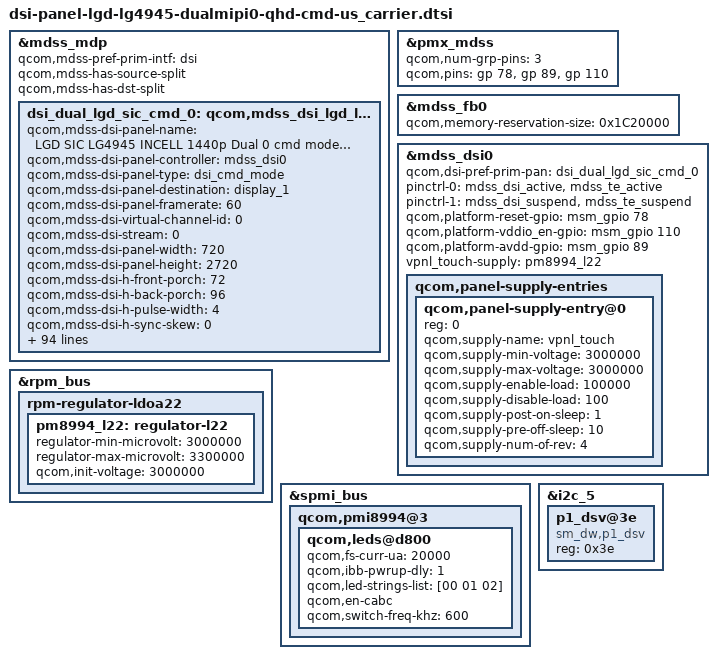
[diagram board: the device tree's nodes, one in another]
/* Copyright (c) 2014, Code Aurora Forum. All rights reserved.
 *
 * This program is free software; you can redistribute it and/or modify
 * it under the terms of the GNU General Public License version 2 and
 * only version 2 as published by the Free Software Foundation.
 *
 * This program is distributed in the hope that it will be useful,
 * but WITHOUT ANY WARRANTY; without even the implied warranty of
 * MERCHANTABILITY or FITNESS FOR A PARTICULAR PURPOSE.  See the
 * GNU General Public License for more details.
 */

&mdss_mdp {
	qcom,mdss-pref-prim-intf = "dsi";
	qcom,mdss-has-source-split;
	qcom,mdss-has-dst-split;
	/*/delete-property/ qcom,mdss-ad-off;*/

	dsi_dual_lgd_sic_cmd_0: qcom,mdss_dsi_lgd_lg4945_1440p_mipi0_cmd {
		qcom,mdss-dsi-panel-name = "LGD SIC LG4945 INCELL 1440p Dual 0 cmd mode dsi panel";
		qcom,mdss-dsi-panel-controller = <&mdss_dsi0>;
		qcom,mdss-dsi-panel-type = "dsi_cmd_mode";
		qcom,mdss-dsi-panel-destination = "display_1";
		qcom,mdss-dsi-panel-framerate = <60>;
		qcom,mdss-dsi-virtual-channel-id = <0>;
		qcom,mdss-dsi-stream = <0>;
		qcom,mdss-dsi-panel-width = <720>;
		qcom,mdss-dsi-panel-height = <2720>;
		qcom,mdss-dsi-h-front-porch = <72>;
		qcom,mdss-dsi-h-back-porch = <96>;
		qcom,mdss-dsi-h-pulse-width = <4>;
		qcom,mdss-dsi-h-sync-skew = <0>;
		qcom,mdss-dsi-v-back-porch = <43>;
		qcom,mdss-dsi-v-front-porch = <8>;
		qcom,mdss-dsi-v-pulse-width = <1>;
		qcom,mdss-dsi-h-left-border = <0>;
		qcom,mdss-dsi-h-right-border = <0>;
		qcom,mdss-dsi-v-top-border = <0>;
		qcom,mdss-dsi-v-bottom-border = <0>;
		qcom,mdss-dsi-bpp = <24>;
		qcom,mdss-dsi-color-order = "rgb_swap_rgb";
		qcom,mdss-dsi-underflow-color = <0xff>;
		qcom,mdss-dsi-border-color = <0>;
		qcom,mdss-dsi-h-sync-pulse = <0>;
		qcom,mdss-dsi-traffic-mode = "burst_mode";
		qcom,mdss-dsi-lane-map = "lane_map_0123";
		qcom,mdss-dsi-lane-hs = <1>;
		qcom,mdss-dsi-bllp-eof-power-mode;
		qcom,mdss-dsi-bllp-power-mode;
		qcom,cmd-sync-wait-broadcast;

		qcom,mdss-dsi-lane-0-state;
		qcom,mdss-dsi-lane-1-state;
		qcom,mdss-dsi-lane-2-state;
		qcom,mdss-dsi-lane-3-state;
		qcom,mdss-dsi-hor-line-idle = <0 40 256>,
						<40 120 128>,
						<120 240 64>;
		qcom,mdss-dsi-panel-timings = [D4 38 38 00 68 5E
									3A 3A 2C 03 04 00];
		qcom,mdss-dsi-reset-sequence = <1 10>, <0 10>, <1 10>;
		qcom,mdss-dsi-t-clk-post = <0x02>;
		lge,mdss-dsi-t-clk-post_for_jdi_ab = <0x32>;
		qcom,mdss-dsi-t-clk-pre = <0x2D>;
		qcom,mdss-dsi-bl-max-level = <4095>;
		qcom,mdss-dsi-dma-trigger = "trigger_sw";
		qcom,mdss-dsi-mdp-trigger = "none";
		qcom,mdss-dsi-bl-pmic-control-type = "bl_ctrl_wled";
		qcom,mdss-dsi-te-pin-select = <1>;
		qcom,mdss-dsi-wr-mem-start = <0x2c>;
		qcom,mdss-dsi-wr-mem-continue = <0x3c>;
		qcom,mdss-dsi-te-dcs-command = <1>;
		qcom,mdss-dsi-te-check-enable;
		qcom,mdss-dsi-te-using-te-pin;
		qcom,suspend-ulps-enabled;
		qcom,mdss-dsi-tx-eot-append;
		qcom,mdss-mdp-transfer-time-us = <15000>;
		/* Partial update */
		qcom,partial-update-enabled;
		qcom,partial-update-roi-merge;
		qcom,panel-roi-alignment = <8 8 4 4 32 32>;
		qcom,mdss-dsi-on-command = [ /*initset v0.9*/
			/* Page Address Set */
			39 01 00 00 00 00 05 2B 00 00 0A 9F
			/* Manufacturer Command Protection */
			15 01 00 00 00 00 02 B0 AC
			/* Touch timing setting to prevent tearing */
			39 01 00 00 00 00 03 44 0A 8C
			/* Tearing Effect Line on */
			15 01 00 00 00 00 02 35 00
			/* Write Control Display */
			15 01 00 00 00 00 02 53 24
			/* Write Display Brightness */
			15 01 00 00 00 00 02 51 FF
			/* Write Content Adaptive Brightness Control */
			15 01 00 00 00 00 02 55 81
			/* Display Control 1 */
			39 01 00 00 00 00 08 B3 0A 14 28 C8 1A 94 02
			/* Display Control 2 */
			39 01 00 00 00 00 0B B4 91 08 0A 0A 0A 0A 14 14 14 14
			/* Display Control 3 */
			39 01 00 00 00 00 0F B5 28 10 20 C8 22 09 09 01 01 00 68 E8 05 05
			/* Display Control 4 */
			39 01 00 00 00 00 06 B6 16 0F 00 08 0A
			/* Panel Setting */
			39 01 00 00 00 00 06 B8 60 91 A7 90 01
			/* Internal Oscillator Setting */
			39 01 00 00 00 00 03 C0 91 00
			/* Power Control 1 */
			39 01 00 00 00 00 06 C1 01 00 F0 C2 CF
			/* Power Control 2 */
			15 01 00 00 00 00 02 C2 CC
			/* Power Control 3 */
			39 01 00 00 00 00 06 C3 35 88 22 26 21
			/* Power Control 5 */
			39 01 00 00 00 00 08 C5 24 20 A0 25 14 34 02
			/* Abrupt Power Off Control */
			15 01 00 00 00 00 02 C9 9F
			/* U2 Control */
			39 01 00 00 00 00 0C CB 86 46 0F 77 06 01 16 0F 08 0A 36
			/* Touch Control */
			39 01 00 00 00 00 10 CD F0 4C 0D 3F 4F 22 22 01 0A 01 02 57 A8 64 64
			/* Positive Gamma Curve for Red */
			39 01 00 00 00 00 0E D0 00 12 1C 2B 36 3E 53 4B 41 36 2A 24 03
			/* Negative Gamma Curve for Red */
			39 01 00 00 00 00 0E D1 00 12 1C 2B 36 3E 53 4B 41 36 2A 24 03
			/* Positive Gamma Curve for  Green */
			39 01 00 00 00 00 0E D2 00 12 1E 2B 36 3E 51 48 3C 2C 15 00 03
			/* Negative Gamma Curve for Green */
			39 01 00 00 00 00 0E D3 00 12 1E 2B 36 3E 51 48 3C 2C 15 00 03
			/* Positive Gamma Curve for Blue */
			39 01 00 00 00 00 0E D4 00 12 1F 2C 37 3F 50 47 3A 2C 15 00 03
			/* Negative Gamma Curve for Blue */
			39 01 00 00 00 00 0E D5 00 12 1F 2C 37 3F 50 47 3A 2C 15 00 03
			/* Left Side GIP Pad Setting */
			39 01 00 00 00 00 16 D6 22 2D 4C 6E 22 22 61 65 67 69 6B 22 71 55 55 55 03 55 55 55 03
			/* Right Side GIP Pad Setting */
			39 01 00 00 00 00 16 D7 22 2D 4C 6E 22 22 60 64 66 68 6a 22 71 55 55 55 03 55 55 55 03
			/* Left Side MUX Pad Setting */
			39 01 00 00 00 00 07 D8 78 77 76 75 74 73
			/* Right Side MUX Pad Setting */
			39 01 00 00 00 00 07 D9 78 77 76 75 74 73
			/* LFD Control */
			39 01 00 00 00 00 08 CA BD BD CC 0C 00 93 00
			/* OTP1 */
			39 01 00 00 00 00 04 E8 00 00 00
			/* Image Enhancement Control */
			15 01 00 00 00 00 02 F0 62
			/* Image Enhancement Control SH */
			39 01 00 00 00 00 05 F2 01 00 04 00
			/* Image Enhancement Control CSC */
			39 01 00 00 00 00 18 F3 00 43 83 C0 FF 30 00 40 80 C0 FF 50 00 3C 7C BC FF 00 00 40 80 C0 FF
			/* Backlight Control */
			39 01 00 00 00 00 07 B9 13 00 00 78 7F 80
			/* SRE Control */
			39 01 00 00 00 00 19 FC 0F 60 75 87 A8 C0 E4 F0 00 40 70 90 A0 B0 C0 F0 00 20 40 60 80 A0 C0 E0
			/* Switchable Power Domain Control */
			39 01 00 00 00 00 03 C6 04 55
			/* Display On */
			05 01 00 00 00 00 01 29
			/* Sleep Out + 100ms */
			05 01 00 00 64 00 01 11
			];
		qcom,mdss-dsi-on-command-state = "dsi_lp_mode";
		qcom,mdss-dsi-off-command = [
			/* Display Off */
			05 01 00 00 0A 00 02 28 00
			/* Memory Option Setting */
			39 01 00 00 00 00 06 E7 00 00 00 00 00
			/* Sleep In */
			05 01 00 00 00 00 02 10 00
			/* Mail box + 105ms */
			39 01 00 00 69 00 05 CC 01 00 00 00
			];
		qcom,mdss-dsi-off-command-state = "dsi_lp_mode";
		qcom,cont-splash-enabled;

		qcom,mode-control-dsi-state = "dsi_lp_mode";
		lge,mode-change-cmds-u2-to-u1 = [
			/* Write Content Adaptive Brightness Control */
			15 01 00 00 00 00 02 55 81
			/* Page Address Set */
			39 01 00 00 00 00 05 2B 00 00 0A 9F
			/* Partial Area */
			39 01 00 00 00 00 05 30 00 A0 0A 9F
			/* Partial Mode On */
			05 01 00 00 00 00 01 12
		];
		lge,mode-change-cmds-u3-to-u1 = [
			/* Write Content Adaptive Brightness Control */
			15 01 00 00 00 00 02 55 81
			/* Memory Option Setting */
			39 01 00 00 00 00 06 E7 00 00 00 00 00
			/* Partial Area */
			39 01 00 00 00 00 05 30 00 A0 0A 9F
			/* Partial Mode On */
			05 01 00 00 00 00 01 12
		];
		lge,mode-change-cmds-u1-to-u2 = [
			/* Write Content Adaptive Brightness Control */
			15 01 00 00 00 00 02 55 00
			/* Tearing Effect Line Off */
			05 01 00 00 00 00 01 34
			/* Memory Option Setting */
			39 01 00 00 00 00 06 E7 00 00 00 30 00
			/* Page Address Set */
			39 01 00 00 00 00 05 2B 00 00 00 9F
			/* Partial Area */
			39 01 00 00 00 00 05 30 00 00 00 9F
			/* Partial Mode On + 20ms Delay */
			05 01 00 00 14 00 01 12
			/* Memory Option Setting */
			39 01 00 00 00 00 06 E7 00 00 00 00 00
		];
		lge,mode-change-cmds-u3-to-u2 = [
			/* Write Content Adaptive Brightness Control */
			15 01 00 00 00 00 02 55 00
			/* Tearing Effect Line Off */
			05 01 00 00 00 00 01 34
			/* Memory Option Setting */
			39 01 00 00 00 00 06 E7 00 00 00 00 00
			/* Page Address Set */
			39 01 00 00 00 00 05 2B 00 00 00 9F
			/* Partial Area */
			39 01 00 00 00 00 05 30 00 00 00 9F
			/* Partial Mode On + 20ms */
			05 01 00 00 14 00 01 12
		];
		lge,mode-change-cmds-u1-to-u3 = [
			/* Write Content Adaptive Brightness Control */
			15 01 00 00 00 00 02 55 81
			/* Memory Option Setting */
			39 01 00 00 00 00 06 E7 00 00 00 00 00
			/* Normmal DisplayMode On */
			05 01 00 00 00 00 01 13
		];
		lge,mode-change-cmds-u2-to-u3 = [
			/* Write Content Adaptive Brightness Control */
			15 01 00 00 00 00 02 55 81
			/* Page Address Set */
			39 01 00 00 00 00 05 2B 00 00 0A 9F
			/* Normmal DisplayMode On + 33ms */
			05 01 00 00 21 00 01 13
		];
		lge,mode-change-cmds-u3-ready = [
			/*  Memory Enable*/
			39 01 00 00 00 00 06 E7 00 00 00 30 00
			/* Page Address Set */
			39 01 00 00 00 00 05 2B 00 00 0A 9F
		];
		lge,mode-change-cmds-proximity-u2-to-u3 = [
			/* Write Content Adaptive Brightness Control */
			15 01 00 00 00 00 02 55 81
			/* Switchable Power Domain Control */
			39 01 00 00 00 00 03 C6 1B 55
			/* Page Address Set */
			39 01 00 00 00 00 05 2B 00 00 0A 9F
			/* Normmal DisplayMode On + 33ms */
			05 01 00 00 21 00 01 13
		];
		lge,mode-change-cmds-proximity-u3-to-u2 = [
			/* Write Content Adaptive Brightness Control */
			15 01 00 00 00 00 02 55 00
			/* Tearing Effect Line Off */
			05 01 00 00 00 00 01 34
			/* Memory Option Setting */
			39 01 00 00 00 00 06 E7 00 00 00 00 00
			/* Switchable Power Domain Control */
			39 01 00 00 00 00 03 C6 04 55
			/* Page Address Set */
			39 01 00 00 00 00 05 2B 00 00 00 9F
			/* Partial Area */
			39 01 00 00 00 00 05 30 00 00 00 9F
			/* Partial Mode On + 20ms */
			05 01 00 00 14 00 01 12
		];

		qcom,sre-control-dsi-state = "dsi_lp_mode";
		lge,sre-cmds-off = [
			15 01 00 00 00 00 02 55 81
		];
		lge,sre-cmds-on = [
			15 01 00 00 00 00 02 55 C1
		];

		qcom,ad-control-dsi-state = "dsi_lp_mode";
		lge,ad-cmds-off = [
		       15 01 00 00 00 00 02 55 81
		];
		lge,ad-cmds-on = [
		       15 01 00 00 00 00 02 55 80
		];

		qcom,img-tune-control-dsi-state = "dsi_lp_mode";
		lge,sharpness-cmds-on = [
			/* Manufacturer Command Protection */
			15 01 00 00 00 00 02 B0 AC
			39 01 00 00 00 00 05 F2 01 00 04 00
		];
		lge,color_enhancement-cmds-on = [
			/* Manufacturer Command Protection */
			15 01 00 00 00 00 02 B0 AC
			15 01 00 00 00 00 02 F0 62
			39 01 00 00 00 00 18 F3 00 43 83 C0 FF 30 00 40 80 C0 FF 50 00 3C 7C BC FF 00 00 40 80 C0 FF
		];

		qcom,blmap-size = <256>;
		qcom,blmap = <
                          0
                          1 5 5 10 10 15 20 20 25 25
                          30 46 62 78 94 110 126 142 158 174
                          190 206 222 238 254 270 286 302 318 334
                          350 366 382 398 414 430 446 462 478 494
                          510 526 542 558 574 590 606 622 638 654
                          670 686 702 718 734 750 766 782 798 814
                          830 846 862 878 894 910 926 942 958 974
                          990 1006 1022 1038 1054 1070 1086 1102 1118 1134
                          1150 1166 1182 1198 1214 1230 1246 1262 1278 1294
                          1310 1326 1342 1358 1374 1390 1406 1422 1438 1454
                          1470 1486 1502 1518 1534 1550 1566 1582 1598 1614
                          1630 1646 1662 1678 1694 1710 1726 1742 1758 1774
                          1790 1806 1822 1838 1854 1870 1886 1902 1918 1934
                          1950 1966 1982 1998 2014 2030 2046 2062 2078 2094
                          2110 2126 2142 2158 2174 2190 2206 2222 2238 2254
                          2270 2286 2302 2318 2334 2350 2366 2382 2398 2414
                          2430 2446 2462 2478 2494 2510 2526 2542 2558 2574
                          2590 2606 2622 2638 2654 2670 2686 2702 2718 2734
                          2750 2766 2782 2798 2814 2830 2846 2862 2878 2894
                          2910 2926 2942 2958 2974 2990 3006 3022 3038 3054
                          3070 3086 3102 3118 3134 3150 3166 3182 3198 3214
                          3230 3246 3262 3278 3294 3310 3326 3342 3358 3374
                          3390 3406 3422 3438 3454 3470 3486 3502 3518 3534
                          3550 3566 3582 3598 3614 3630 3646 3662 3678 3694
                          3710 3726 3742 3758 3774 3790 3806 3822 3838 3854
                          3870 3886 3902 3918 4000
		>;
		qcom,mdss-pan-physical-width-dimension = <71>;
		qcom,mdss-pan-physical-height-dimension = <135>;

		lge,panel_power_sequence = <
			0    /*pre_msm_dss_enable_vreg*/
			0    /*post_msm_dss_enable_vreg*/
			0    /*pre_mdss_dsi_panel_reset*/
			0    /*post_mdss_dsi_panel_reset*/
			1    /*pre_mdss_dsi_panel_power_ctrl*/
			1    /*post_mdss_dsi_panel_power_ctrl*/
			0    /*post_mdss_dsi_blank*/
			1    /*post_mdss_dsi_panel_on*/
			0    /*post_mdss_dsi_panel_off*/
			1    /*lge_mdss_dsi_event_handler*/
			1    /*lge_msm_dss_enable_vreg*/
			1    /*lge_mdss_dsi_request_gpios*/
			1    /*lge_mdss_dsi_panel_reset*/
			0    /*lge_mdss_dsi_lane_config*/
			1    /*lge_mdss_dsi_ctrl_probe*/
			1    /*lge_dsi_panel_device_register*/
			1    /*lge_mdss_panel_parse_dt*/
			0    /*lge_panel_device_create*/
			1    /*lge_mdss_fb_set_bl_brightness*/
			1    /*lge_mdss_fb_blank_unblank*/
			1    /*lge_mdss_dsi_cmdlist_commit*/
			1    /*lge_mdss_dsi_panel_init*/
			1    /*lge_dump_mdss_reg*/
			1    /*lge_mdss_xlog_tout_handler_default*/
			0    /*lge_mdss_create_xlog_debug*/
			>;
	};
};

&pmx_mdss {
	qcom,num-grp-pins = <3>;
	qcom,pins = <&gp 78>, <&gp 89>, <&gp 110>;
};

&mdss_fb0 {
	qcom,memory-reservation-size = <0x1C20000>;
};

&mdss_dsi0 {
	qcom,dsi-pref-prim-pan = <&dsi_dual_lgd_sic_cmd_0>;
	pinctrl-names = "mdss_default", "mdss_sleep";

	/* pinctrl-0 = <&mdss_dsi_active>; */
	/* pinctrl-1 = <&mdss_dsi_suspend>; */
	/* Add TE pin control status on the PINCTRL structure */
	pinctrl-0 = <&mdss_dsi_active &mdss_te_active>;
	pinctrl-1 = <&mdss_dsi_suspend &mdss_te_suspend>;

	qcom,platform-reset-gpio = <&msm_gpio 78 0>;
	/* qcom,dsi-panel-bias-vreg; */
	qcom,platform-vddio_en-gpio = <&msm_gpio 110 0>;
	qcom,platform-avdd-gpio = <&msm_gpio 89 0>;

	vpnl_touch-supply =  <&pm8994_l22>;

	qcom,panel-supply-entries {
		#address-cells = <1>;
		#size-cells = <0>;

		qcom,panel-supply-entry@0 {
			reg = <0>;
			qcom,supply-name = "vpnl_touch";
			qcom,supply-min-voltage = <3000000>;
			qcom,supply-max-voltage = <3000000>;
			qcom,supply-enable-load = <100000>;
			qcom,supply-disable-load = <100>;
			qcom,supply-post-on-sleep = <1>;
			qcom,supply-pre-off-sleep = <10>;

			qcom,supply-num-of-rev = <4>;
		};
	};
};

/* RPM controlled regulators: */

&rpm_bus {
	rpm-regulator-ldoa22 {
		status = "okay";
		pm8994_l22: regulator-l22 {
			regulator-min-microvolt = <3000000>;
			regulator-max-microvolt = <3300000>;
			qcom,init-voltage = <3000000>;
			status = "okay";
		};
	};
};

&spmi_bus {
	qcom,pmi8994@3 {
		qcom,leds@d800 {
			qcom,fs-curr-ua = <20000>;
			qcom,ibb-pwrup-dly = <1>;
			qcom,led-strings-list = [00 01 02];
			qcom,en-cabc;
			qcom,switch-freq-khz = <600>;
		};
	};
};

&i2c_5 {
    p1_dsv@3e {
        status = "ok";
        compatible = "sm_dw,p1_dsv";
        reg = <0x3e>;
    };
};

#include "dsi-panel-lgd-lg4945-dualmipi0-qhd-cmd-rev0-us_carrier.dtsi"
#include "dsi-panel-lgd-lg4945-dualmipi0-qhd-cmd-rev1-us_carrier.dtsi"
#include "dsi-panel-lgd-lg4945-dualmipi0-qhd-cmd-rev2-us_carrier.dtsi"
#include "dsi-panel-lgd-lg4945-dualmipi0-qhd-cmd-rev3-us_carrier.dtsi"
